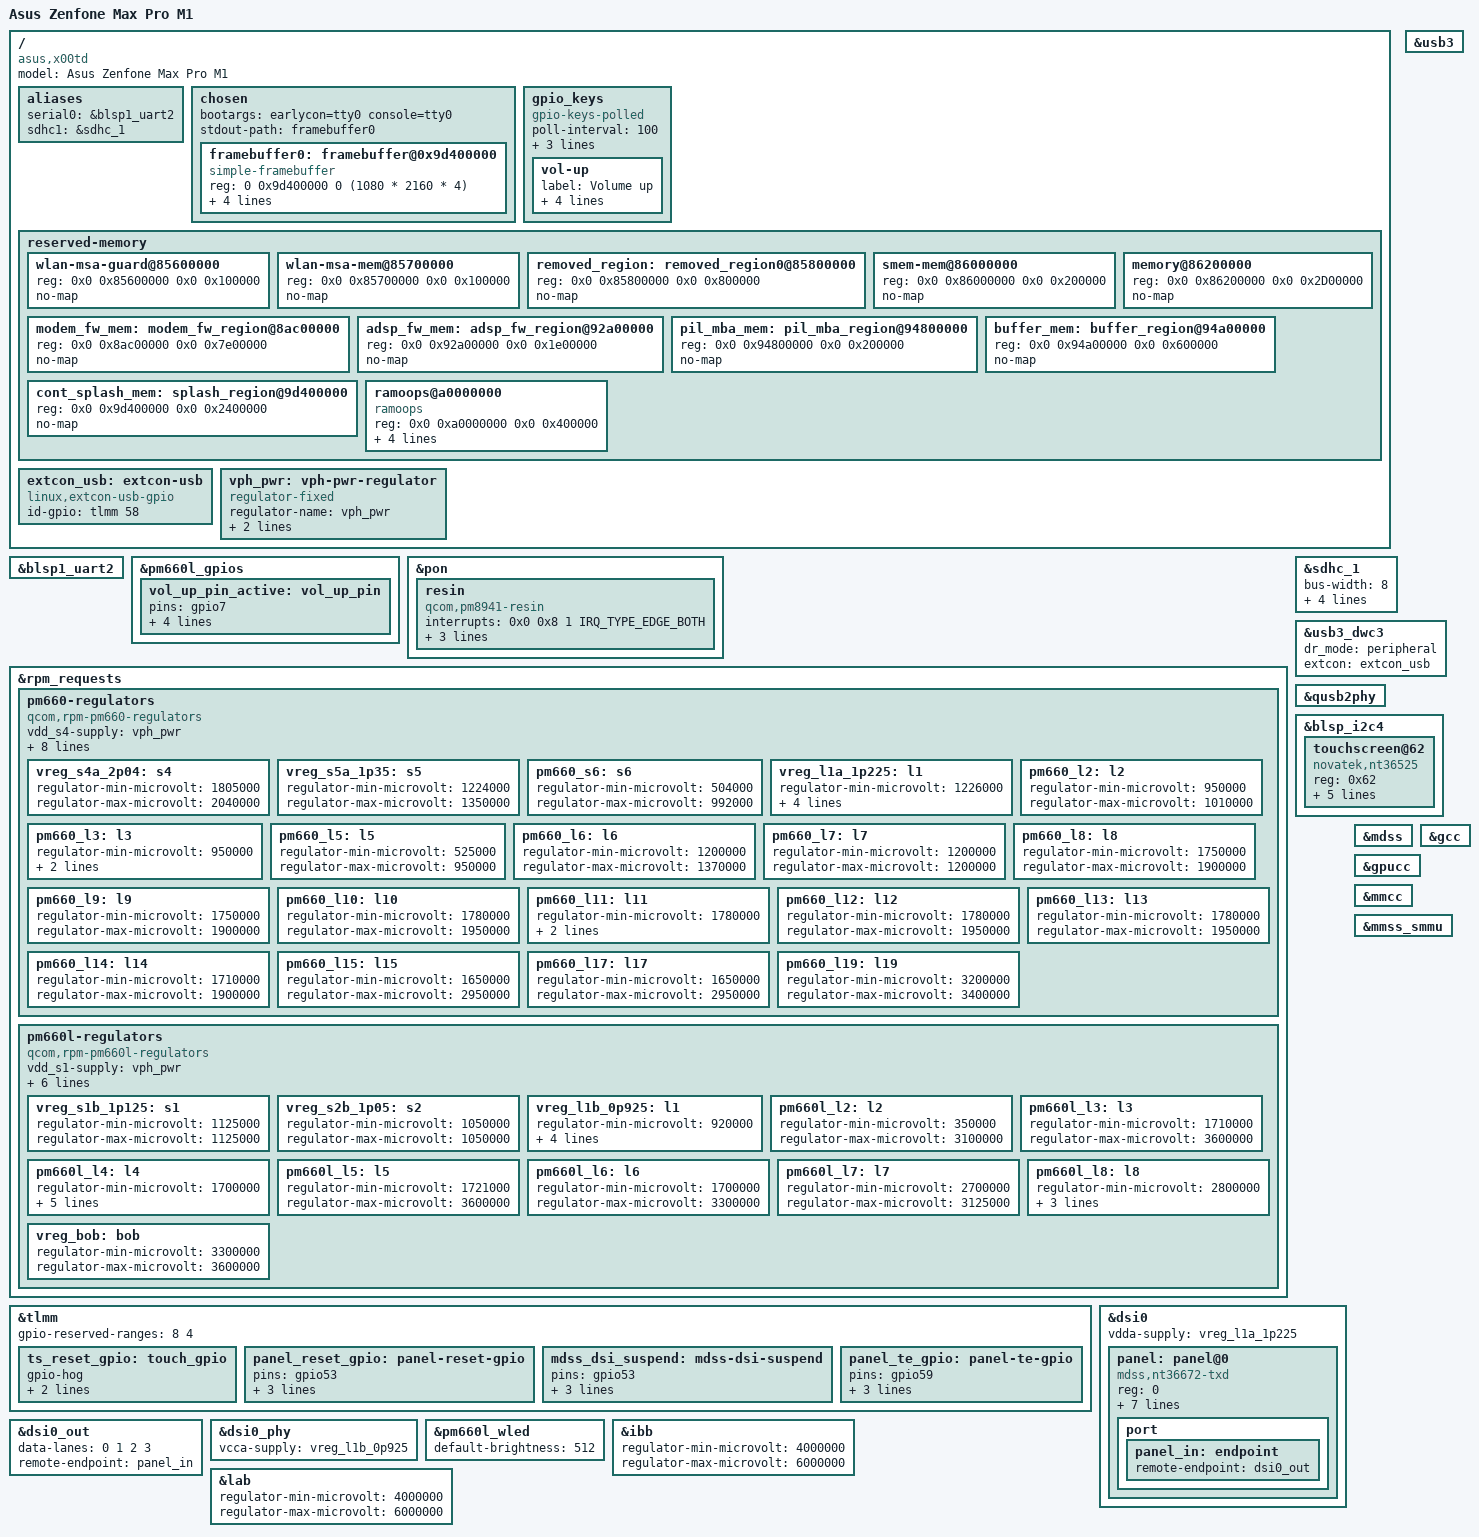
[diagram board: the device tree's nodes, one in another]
// SPDX-License-Identifier: GPL-2.0-only
/*
 * Copyright (c) 2020, Alexey Minnekhanov <alexey.min@gmail.com>
 */

/dts-v1/;

#include <dt-bindings/gpio/gpio.h>
#include <dt-bindings/input/linux-event-codes.h>
#include <dt-bindings/interrupt-controller/irq.h>
#include <dt-bindings/pinctrl/qcom,pmic-gpio.h>
#include "sdm636.dtsi"
#include "pm660.dtsi"
#include "pm660l.dtsi"

/ {
	model = "Asus Zenfone Max Pro M1";
	compatible = "asus,x00td", "qcom,sdm660", "qcom, sdm636";

	aliases {
		serial0 = &blsp1_uart2;
		sdhc1 = &sdhc_1; /* SDC1 eMMC slot */
	};

	chosen {
		bootargs = "earlycon=tty0 console=tty0";

		#address-cells = <2>;
		#size-cells = <2>;
		ranges;

		stdout-path = "framebuffer0";

		framebuffer0: framebuffer@0x9d400000 {
		compatible = "simple-framebuffer";
		reg = <0 0x9d400000 0 (1080 * 2160 * 4)>;
		width = <1080>;
		height = <2160>;
		stride = <(1080 * 4)>;
		format = "a8r8g8b8";
		};
	};

	gpio_keys {
		/* compatible = "gpio-keys"; does not work */
		compatible = "gpio-keys-polled";
		poll-interval = <100>; /* needed only for gpio-keys-polled */
		label = "Volume up";
		autorepeat;
		pinctrl-names = "default";
		pinctrl-0 = <&vol_up_pin_active>;

		vol-up {
			label = "Volume up";
			gpios = <&pm660l_gpios 7 GPIO_ACTIVE_LOW>;
			linux,input-type = <EV_KEY>;
			linux,code = <KEY_VOLUMEUP>;
			debounce-interval = <15>;
			/* wakeup-source; Note: gpio-keys-polled does not support this */
		};
	};

	reserved-memory {
		#address-cells = <2>;
		#size-cells = <2>;
		ranges;
		
		/delete-node/ memory@85e00000;
		wlan-msa-guard@85600000 {
			reg = <0x0 0x85600000 0x0 0x100000>;
			no-map;
		};

		wlan-msa-mem@85700000 {
			reg = <0x0 0x85700000 0x0 0x100000>;
			no-map;
		};

		/* removed_regions in downstream / qhee_code */
		/delete-node/ qhee-code@85800000;
		removed_region: removed_region0@85800000 {
			reg = <0x0 0x85800000 0x0 0x800000>;
			no-map;
		};

		smem-mem@86000000 {
			reg = <0x0 0x86000000 0x0 0x200000>;
			no-map;
		};

		/* tz_mem */
		memory@86200000 {
			reg = <0x0 0x86200000 0x0 0x2D00000>;
			/* 0x86200000 + 0x2D00000 = 0x88F00000 */
			no-map;
		};

		/* downstream has this: */
		/* removed_regions@85800000 {
			reg = <0x0 0x85800000 0x0 0x3700000>;
			no-map;
		}; */
		/* which covers region starting from removed_regions to 0x88F00000 (end of our tz_mem) */

		/* modem_fw_region */
		modem_fw_mem: modem_fw_region@8ac00000 {
			reg = <0x0 0x8ac00000 0x0 0x7e00000>;
			no-map;
		};

		/* adsp_fw_region */
		/delete-node/ adsp-region@f6000000;
		adsp_fw_mem: adsp_fw_region@92a00000 {
			reg = <0x0 0x92a00000 0x0 0x1e00000>;
			no-map;
		};

		/* pil_mba_mem */
		pil_mba_mem: pil_mba_region@94800000 {
			reg = <0x0 0x94800000 0x0 0x200000>;
			no-map;
		};

		/* cdsp_fw_region */
		/delete-node/ tzbuffer@94a00000;
		buffer_mem: buffer_region@94a00000 {
			reg = <0x0 0x94a00000 0x0 0x600000>;
			no-map;
		};

		/* cont_splash_region / framebuffer */
		cont_splash_mem: splash_region@9d400000 {
			reg = <0x0 0x9d400000 0x0 0x2400000>;
			no-map;
		};
		ramoops@a0000000 {
			compatible = "ramoops";
			reg = <0x0 0xa0000000 0x0 0x400000>;
			console-size = <0x20000>;
			record-size = <0x20000>;
			ftrace-size = <0x0>;
			pmsg-size = <0x20000>;
		};
	};
	
	/*
	 * Until we hook up type-c detection, we
	 * have to stick with this. But it works.
	 */
	extcon_usb: extcon-usb {
		compatible = "linux,extcon-usb-gpio";
		id-gpio = <&tlmm 58 GPIO_ACTIVE_HIGH>;
	};

	vph_pwr: vph-pwr-regulator {
		compatible = "regulator-fixed";
		regulator-name = "vph_pwr";
		regulator-always-on;
		regulator-boot-on;
	};
};

&blsp1_uart2 {
	status = "okay";
	pinctrl-names = "default";
	//pinctrl-0 = <&uart_console_active>;
};

&pm660l_gpios {
	vol_up_pin_active: vol_up_pin {
		pins = "gpio7";
		function = "normal";
		input-enable;
		bias-pull-up;
		qcom,drive-strength = <PMIC_GPIO_STRENGTH_NO>;
	};
};

&pon {
	resin {
		compatible = "qcom,pm8941-resin";
		interrupts = <0x0 0x8 1 IRQ_TYPE_EDGE_BOTH>;
		debounce = <15625>;
		bias-pull-up;
		linux,code = <KEY_VOLUMEDOWN>;
	};
};

&rpm_requests {
	pm660-regulators {
		compatible = "qcom,rpm-pm660-regulators";
		vdd_s4-supply = <&vph_pwr>;
		vdd_s5-supply = <&vph_pwr>;
		vdd_s6-supply = <&vph_pwr>;
		vdd_l1_l6_l7-supply = <&vreg_s5a_1p35>;
		vdd_l2_l3-supply = <&vreg_s2b_1p05>;
		vdd_l5-supply =  <&vreg_s2b_1p05>;
		vdd_l8_l9_l10_l11_l12_l13_l14-supply = <&vreg_s4a_2p04>;
		vdd_l15_l16_l17_l18_l19-supply = <&vreg_bob>;

		vreg_s4a_2p04: s4 {
			regulator-min-microvolt = <1805000>;
			regulator-max-microvolt = <2040000>;
		};
		vreg_s5a_1p35: s5 {
			regulator-min-microvolt = <1224000>;
			regulator-max-microvolt = <1350000>;
		};
		pm660_s6: s6 {
			regulator-min-microvolt = <504000>;
			regulator-max-microvolt = <992000>;
		};
		/*pm660_l1: l1 {
			regulator-min-microvolt = <1150000>;
			regulator-max-microvolt = <1250000>;
		};*/
		vreg_l1a_1p225: l1 {
			regulator-min-microvolt = <1226000>;
			regulator-max-microvolt = <1250000>;
			regulator-enable-ramp-delay = <250>;
			regulator-ramp-delay = <0>;
			regulator-allow-set-load;
			/* regulator-always-on; */
		};
		pm660_l2: l2 {
			regulator-min-microvolt = <950000>;
			regulator-max-microvolt = <1010000>;
		};
		pm660_l3: l3 {
			regulator-min-microvolt = <950000>;
			regulator-max-microvolt = <1010000>;
			regulator-always-on;
		};
		pm660_l5: l5 {
			regulator-min-microvolt = <525000>;
			regulator-max-microvolt = <950000>;
		};
		pm660_l6: l6 {
			regulator-min-microvolt = <1200000>;
			regulator-max-microvolt = <1370000>;
		};
		pm660_l7: l7 {
			regulator-min-microvolt = <1200000>;
			regulator-max-microvolt = <1200000>;
		};
		pm660_l8: l8 {
			regulator-min-microvolt = <1750000>;
			regulator-max-microvolt = <1900000>;
			//regulator-boot-on;
			//regulator-allow-set-load;
		};
		pm660_l9: l9 {
			regulator-min-microvolt = <1750000>;
			regulator-max-microvolt = <1900000>;
		};
		pm660_l10: l10 {
			regulator-min-microvolt = <1780000>;
			regulator-max-microvolt = <1950000>;
		};
		pm660_l11: l11 {
			regulator-min-microvolt = <1780000>;
			regulator-max-microvolt = <1950000>;
			regulator-always-on;
		};
		pm660_l12: l12 {
			regulator-min-microvolt = <1780000>;
			regulator-max-microvolt = <1950000>;
		};
		pm660_l13: l13 {
			regulator-min-microvolt = <1780000>;
			regulator-max-microvolt = <1950000>;
		};
		pm660_l14: l14 {
			regulator-min-microvolt = <1710000>;
			regulator-max-microvolt = <1900000>;
		};
		pm660_l15: l15 {
			regulator-min-microvolt = <1650000>;
			regulator-max-microvolt = <2950000>;
		};
		pm660_l17: l17 {
			regulator-min-microvolt = <1650000>;
			regulator-max-microvolt = <2950000>;
		};
		pm660_l19: l19 {
			regulator-min-microvolt = <3200000>;
			regulator-max-microvolt = <3400000>;
		};
	};

	pm660l-regulators {
		compatible = "qcom,rpm-pm660l-regulators";

		vdd_s1-supply = <&vph_pwr>;
		vdd_s2-supply = <&vph_pwr>;
		vdd_l1_l9_l10-supply = <&vreg_s2b_1p05>;
		vdd_l2-supply = <&vreg_bob>;
		vdd_l3_l5_l7_l8-supply = <&vreg_bob>;
		vdd_l4_l6-supply = <&vreg_bob>;
		/* downstream has this in dmesg: pm660l_l7: supplied by pm660_l10, WTF */
		vdd_bob-supply = <&vph_pwr>;

		vreg_s1b_1p125: s1 {
			regulator-min-microvolt = <1125000>;
			regulator-max-microvolt = <1125000>;
		};
		vreg_s2b_1p05: s2 {
			regulator-min-microvolt = <1050000>;
			regulator-max-microvolt = <1050000>;
		};
		/*pm660l_l1: l1 {
			regulator-min-microvolt = <800000>;
			regulator-max-microvolt = <925000>;
		};*/
		vreg_l1b_0p925: l1 {
			regulator-min-microvolt = <920000>;
			regulator-max-microvolt = <928000>;
			regulator-enable-ramp-delay = <250>;
			regulator-ramp-delay = <0>;
			regulator-allow-set-load;
		};
		pm660l_l2: l2 {
			regulator-min-microvolt = <350000>;
			regulator-max-microvolt = <3100000>;
		};
		pm660l_l3: l3 {
			regulator-min-microvolt = <1710000>;
			regulator-max-microvolt = <3600000>;
		};
		pm660l_l4: l4 {
			regulator-min-microvolt = <1700000>;
			regulator-max-microvolt = <2950000>;
			/* regulator-boot-on;   - nope, breaks things */
			regulator-allow-set-load;         /* opendata had this */
			regulator-system-load = <200000>; /* opendata had this */
			regulator-enable-ramp-delay = <250>;
			regulator-ramp-delay = <0>;
		};
		pm660l_l5: l5 {
			regulator-min-microvolt = <1721000>;
			regulator-max-microvolt = <3600000>;
		};
		pm660l_l6: l6 {
			regulator-min-microvolt = <1700000>;
			regulator-max-microvolt = <3300000>;
		};
		pm660l_l7: l7 {
			regulator-min-microvolt = <2700000>;
			regulator-max-microvolt = <3125000>;
		};
		pm660l_l8: l8 {
			regulator-min-microvolt = <2800000>;
			regulator-max-microvolt = <2800000>;
			regulator-enable-ramp-delay = <250>;
			regulator-ramp-delay = <0>;
		};
		vreg_bob: bob {
			regulator-min-microvolt = <3300000>;
			regulator-max-microvolt = <3600000>;
		};
	};
};

&sdhc_1 {
	status = "okay";
	bus-width = <8>;
	non-removable;
	mmc-ddr-1_8v;    
	mmc-hs200-1_8v;  
	mmc-hs400-1_8v; 
	//vmmc-supply = <&pm660l_l4>; 
	//vqmmc-supply = <&pm660_l8>;  
};

&tlmm {
	gpio-reserved-ranges = <8 4>;
	ts_reset_gpio: touch_gpio {
    	gpio-hog;
    	gpios = <66 GPIO_ACTIVE_HIGH>;
    	output-high;
	};
	panel_reset_gpio: panel-reset-gpio {
		pins = "gpio53";
		function = "gpio";
		drive-strength = <8>;
		bias-disable;
	};
	mdss_dsi_suspend: mdss-dsi-suspend {
		pins = "gpio53";
		function = "gpio";
		drive-strength = <2>;
		bias-pull-down;
	};

	panel_te_gpio: panel-te-gpio {
		pins = "gpio59";
		function = "gpio";
		drive-strength = <2>;
		bias-pull-down;
	};
};

&usb3 {
	status = "okay";
};

&usb3_dwc3 {
	status = "okay";
	dr_mode = "peripheral";
	extcon = <&extcon_usb>;
};

&qusb2phy {
	status = "okay";
};

&blsp_i2c4 {
      #address-cells = <1>;
      #size-cells = <0>;

      touchscreen@62 {
	compatible = "novatek,nt36525";
        reg = <0x62>;
        
	interrupt-parent = <&tlmm>;
        interrupts = <45 IRQ_TYPE_EDGE_RISING>;
        reset-gpios = <&tlmm 102 GPIO_ACTIVE_HIGH>;

        vdd-supply = <&pm660l_l3>;
        vio-supply = <&pm660_l11>;
	//ibb-supply = <&ibb>;
        //lab-supply = <&lab>;
	};
};

/*&spmi_bus {
	pmic@3 {
	labibb: qcom-lab-ibb-regulator {
			compatible = "qcom,pmi8998", "qcom,spmi-pmic";
			#address-cells = <1>;
			#size-cells = <0>;
			status = "okay";
		labibb {
			compatible = "qcom,pmi8998-lab-ibb";
			ibb: ibb {
				reg = <0xdc00 0x100>;
				interrupts = <0x3 0xdc 0x2 IRQ_TYPE_EDGE_RISING>,
					     <0x3 0xdc 0x0 IRQ_TYPE_LEVEL_HIGH>;
				interrupt-names = "sc-err", "ocp";
			};

			lab: lab {
				reg = <0xde00 0x100>;
				interrupts = <0x3 0xde 0x1 IRQ_TYPE_EDGE_RISING>,
					     <0x3 0xde 0x0 IRQ_TYPE_LEVEL_LOW>;
				interrupt-names = "sc-err", "ocp";
			};
		};
	};
	};
};*/


/*labibb: qcom-lab-ibb-regulator {
                        compatible = "qcom,pmi8998", "qcom,spmi-pmic";
                        //compatible = "qcom,pmi8998-lab-ibb";
                        #address-cells = <1>;
                        #size-cells = <1>;
                        status = "okay";
                labibb {
                        compatible = "qcom,pmi8998-lab-ibb";

                ibb: ibb {
                                reg = <0xdc00 0x100>;
                                interrupts = <0x3 0xdc 0x2 IRQ_TYPE_EDGE_RISING>,
                                             <0x3 0xdc 0x0 IRQ_TYPE_LEVEL_HIGH>;
                                interrupt-names = "sc-err", "ocp";
                                // copypaste from downstream device tree
                                reg-names = "ibb";
                                regulator-name = "ibb_reg";

                                regulator-min-microvolt = <4000000>;
                                regulator-max-microvolt = <6300000>;

                                qcom,qpnp-ibb-min-voltage = <1400000>;
                                qcom,qpnp-ibb-step-size = <100000>;
                                qcom,qpnp-ibb-slew-rate = <2000000>;
                                qcom,qpnp-ibb-init-voltage = <4000000>;
                                qcom,qpnp-ibb-init-amoled-voltage = <4000000>;
                        };

                lab: lab {
                                reg = <0xde00 0x100>;
                                reg-names = "lab";
                                regulator-name = "lab_reg";

                                regulator-min-microvolt = <4600000>;
                                regulator-max-microvolt = <6100000>;

                                qcom,qpnp-lab-min-voltage = <4600000>;
                                qcom,qpnp-lab-step-size = <100000>;
                                qcom,qpnp-lab-slew-rate = <5000>;
                                qcom,qpnp-lab-init-voltage = <4600000>;
                                qcom,qpnp-lab-init-amoled-voltage = <4600000>;

                                qcom,notify-lab-vreg-ok-sts;
                                interrupts = <0x3 0xde 0x1 IRQ_TYPE_EDGE_RISING>,
                                             <0x3 0xde 0x0 IRQ_TYPE_LEVEL_LOW>;
                                interrupt-names = "sc-err", "ocp";
                        };
                };
        };*/

&dsi0 {
	#address-cells = <1>;
	#size-cells = <0>;
	status = "okay";
	vdda-supply = <&vreg_l1a_1p225>;
	panel: panel@0 {
		compatible = "mdss,nt36672-txd";
		reg = <0>;

		backlight = <&pm660l_wled>;

		ibb-supply = <&ibb>;
                lab-supply = <&lab>;
                vddio-supply = <&pm660_l11>;
		//reset-gpios = <&tlmm XY GPIO_ACTIVE_LOW>;
		reset-gpios = <&tlmm 53 GPIO_ACTIVE_HIGH>;
		disp-te-gpios = <&tlmm 59 GPIO_ACTIVE_HIGH>;

		pinctrl-names = "default";
		pinctrl-0 = <&panel_reset_gpio &panel_te_gpio>;
		port {
			panel_in: endpoint {
				remote-endpoint = <&dsi0_out>;
			};
		};
	};
};

&dsi0_out {
	data-lanes = <0 1 2 3>;
	remote-endpoint = <&panel_in>;
};
&mdss {
	status = "okay";
};

&dsi0_phy {
	status = "okay";
	vcca-supply = <&vreg_l1b_0p925>;
};

&pm660l_wled {
        status = "okay";
        default-brightness = <512>;
};

&blsp_i2c4 {
	status = "okay";
};

&ibb {
                regulator-min-microvolt = <4000000>;
                regulator-max-microvolt = <6000000>;
};

&lab {
                regulator-min-microvolt = <4000000>;
                regulator-max-microvolt = <6000000>;
};

&gcc {
	status = "ok";
};

&gpucc {
	status = "ok";
};

&mmcc {
	status = "ok";
};

&mmss_smmu {
	status = "ok";
};
